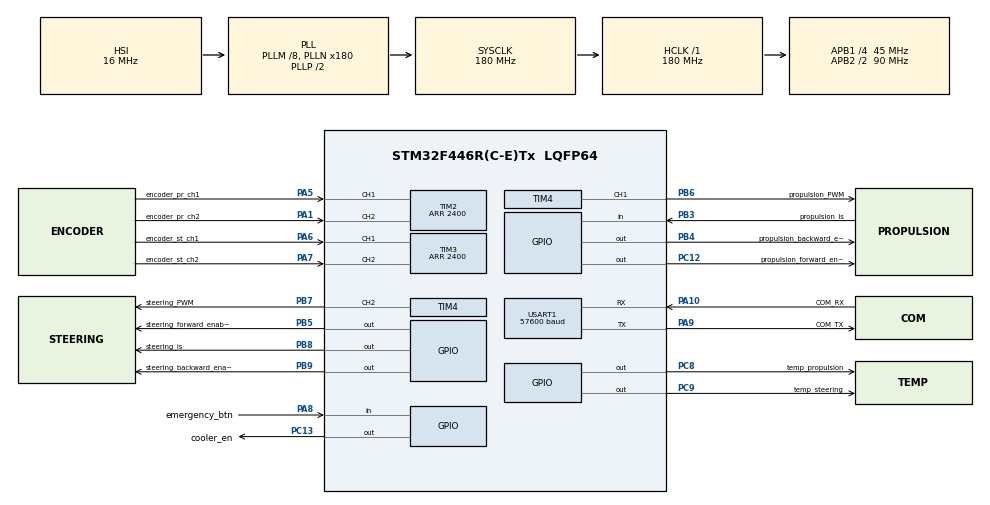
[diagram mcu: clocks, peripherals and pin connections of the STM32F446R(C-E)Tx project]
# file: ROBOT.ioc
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Dma.Request0=USART1_RX
Dma.Request1=USART1_TX
Dma.USART1_RX.0.Direction=DMA_PERIPH_TO_MEMORY
Dma.USART1_RX.0.FIFOMode=DMA_FIFOMODE_DISABLE
Dma.USART1_RX.0.Instance=DMA2_Stream2
Dma.USART1_RX.0.MemDataAlignment=DMA_MDATAALIGN_BYTE
Dma.USART1_RX.0.MemInc=DMA_MINC_ENABLE
Dma.USART1_RX.0.Mode=DMA_NORMAL
Dma.USART1_RX.0.PeriphDataAlignment=DMA_PDATAALIGN_BYTE
Dma.USART1_RX.0.PeriphInc=DMA_PINC_DISABLE
Dma.USART1_RX.0.Priority=DMA_PRIORITY_VERY_HIGH
Dma.USART1_TX.1.Direction=DMA_MEMORY_TO_PERIPH
Dma.USART1_TX.1.FIFOMode=DMA_FIFOMODE_DISABLE
Dma.USART1_TX.1.Instance=DMA2_Stream7
Dma.USART1_TX.1.MemDataAlignment=DMA_MDATAALIGN_BYTE
Dma.USART1_TX.1.MemInc=DMA_MINC_ENABLE
Dma.USART1_TX.1.Mode=DMA_NORMAL
Dma.USART1_TX.1.PeriphDataAlignment=DMA_PDATAALIGN_BYTE
Dma.USART1_TX.1.PeriphInc=DMA_PINC_DISABLE
Dma.USART1_TX.1.Priority=DMA_PRIORITY_VERY_HIGH
Mcu.Family=STM32F4
Mcu.Name=STM32F446R(C-E)Tx
Mcu.Package=LQFP64
NVIC.DMA2_Stream2_IRQn=true\:0\:0\:false\:false\:true\:false\:true
NVIC.DMA2_Stream7_IRQn=true\:0\:0\:false\:false\:true\:false\:true
NVIC.PriorityGroup=NVIC_PRIORITYGROUP_4
NVIC.TIM1_UP_TIM10_IRQn=true\:0\:0\:false\:false\:true\:false\:true
NVIC.TimeBase=TIM1_UP_TIM10_IRQn
NVIC.TimeBaseIP=TIM1
NVIC.USART1_IRQn=true\:0\:0\:false\:false\:true\:true\:true
PA1.GPIO_Label=encoder_pr_ch2
PA1.GPIO_PuPd=GPIO_PULLUP
PA1.Signal=S_TIM2_CH2
PA10.GPIO_Label=COM_RX
PA10.Mode=Asynchronous
PA10.Signal=USART1_RX
PA13.Mode=Serial_Wire
PA13.Signal=SYS_JTMS-SWDIO
PA14.Mode=Serial_Wire
PA14.Signal=SYS_JTCK-SWCLK
PA5.GPIO_Label=encoder_pr_ch1
PA5.GPIO_PuPd=GPIO_PULLUP
PA5.Signal=S_TIM2_CH1_ETR
PA6.GPIO_Label=encoder_st_ch1
PA6.GPIO_PuPd=GPIO_PULLUP
PA6.Signal=S_TIM3_CH1
PA7.GPIO_Label=encoder_st_ch2
PA7.GPIO_PuPd=GPIO_PULLUP
PA7.Signal=S_TIM3_CH2
PA8.GPIO_Label=emergency_btn
PA8.GPIO_PuPd=GPIO_PULLUP
PA8.Signal=GPIO_Input
PA9.GPIO_Label=COM_TX
PA9.Mode=Asynchronous
PA9.Signal=USART1_TX
PB3.GPIO_Label=propulsion_is
PB3.Signal=GPIO_Input
PB4.GPIO_Label=propulsion_backward_enable
PB4.GPIO_Speed=GPIO_SPEED_FREQ_VERY_HIGH
PB4.PinState=GPIO_PIN_RESET
PB4.Signal=GPIO_Output
PB5.GPIO_Label=steering_forward_enable
PB5.GPIO_Speed=GPIO_SPEED_FREQ_VERY_HIGH
PB5.PinState=GPIO_PIN_RESET
PB5.Signal=GPIO_Output
PB6.GPIO_Label=propulsion_PWM
PB6.GPIO_Speed=GPIO_SPEED_FREQ_VERY_HIGH
PB6.Signal=S_TIM4_CH1
PB7.GPIO_Label=steering_PWM
PB7.GPIO_Speed=GPIO_SPEED_FREQ_VERY_HIGH
PB7.Signal=S_TIM4_CH2
PB8.GPIO_Label=steering_is
PB8.Signal=GPIO_Output
PB9.GPIO_Label=steering_backward_enable
PB9.GPIO_Speed=GPIO_SPEED_FREQ_VERY_HIGH
PB9.PinState=GPIO_PIN_RESET
PB9.Signal=GPIO_Output
PC12.GPIO_Label=propulsion_forward_enable
PC12.GPIO_Speed=GPIO_SPEED_FREQ_VERY_HIGH
PC12.PinState=GPIO_PIN_RESET
PC12.Signal=GPIO_Output
PC13.GPIO_Label=cooler_en
PC13.Signal=GPIO_Output
PC8.GPIO_Label=temp_propulsion
PC8.GPIO_ModeDefaultOutputPP=GPIO_MODE_OUTPUT_OD
PC8.GPIO_PuPd=GPIO_PULLUP
PC8.GPIO_Speed=GPIO_SPEED_FREQ_VERY_HIGH
PC8.Signal=GPIO_Output
PC9.GPIO_Label=temp_steering
PC9.GPIO_ModeDefaultOutputPP=GPIO_MODE_OUTPUT_OD
PC9.GPIO_PuPd=GPIO_PULLUP
PC9.GPIO_Speed=GPIO_SPEED_FREQ_VERY_HIGH
PC9.Signal=GPIO_Output
ProjectManager.HeapSize=0x1800
ProjectManager.StackSize=0x1800
ProjectManager.TargetToolchain=STM32CubeIDE
RCC.AHBFreq_Value=180000000
RCC.APB1CLKDivider=RCC_HCLK_DIV4
RCC.APB1Freq_Value=45000000
RCC.APB1TimFreq_Value=90000000
RCC.APB2CLKDivider=RCC_HCLK_DIV2
RCC.APB2Freq_Value=90000000
RCC.APB2TimFreq_Value=180000000
RCC.CortexFreq_Value=180000000
RCC.HCLKFreq_Value=180000000
RCC.PLLM=8
RCC.PLLN=180
RCC.SYSCLKFreq_VALUE=180000000
RCC.SYSCLKSource=RCC_SYSCLKSOURCE_PLLCLK
RCC.USBFreq_Value=180000000
RCC.VCOOutputFreq_Value=360000000
SH.S_TIM2_CH1_ETR.0=TIM2_CH1,Encoder_Interface
SH.S_TIM2_CH2.0=TIM2_CH2,Encoder_Interface
SH.S_TIM3_CH1.0=TIM3_CH1,Encoder_Interface
SH.S_TIM3_CH2.0=TIM3_CH2,Encoder_Interface
SH.S_TIM4_CH1.0=TIM4_CH1,PWM Generation1 CH1
SH.S_TIM4_CH2.0=TIM4_CH2,PWM Generation2 CH2
TIM2.EncoderMode=TIM_ENCODERMODE_TI12
TIM2.IC1Filter=10
TIM2.IC2Filter=10
TIM2.Period=2400
TIM3.EncoderMode=TIM_ENCODERMODE_TI12
TIM3.IC1Filter=10
TIM3.IC2Filter=10
TIM3.Period=2400
TIM4.Channel-PWM\ Generation1\ CH1=TIM_CHANNEL_1
TIM4.Channel-PWM\ Generation2\ CH2=TIM_CHANNEL_2
TIM4.OCFastMode_PWM-PWM\ Generation1\ CH1=TIM_OCFAST_ENABLE
TIM4.OCFastMode_PWM-PWM\ Generation2\ CH2=TIM_OCFAST_ENABLE
TIM4.OCPolarity_1=TIM_OCPOLARITY_HIGH
TIM4.OCPolarity_2=TIM_OCPOLARITY_HIGH
TIM4.Period=300
TIM4.Prescaler=1199
TIM5.CounterMode=TIM_COUNTERMODE_DOWN
TIM5.Period=0
TIM5.Prescaler=(SystemCoreClock/1e6)/4 -1
USART1.BaudRate=57600
USART1.VirtualMode=VM_ASYNC
VP_IWDG_VS_IWDG.Mode=IWDG_Activate
VP_SYS_VS_tim1.Mode=TIM1
VP_TIM5_VS_ClockSourceINT.Mode=Internal
board=custom

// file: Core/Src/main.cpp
/* USER CODE BEGIN Header */
/**
  ******************************************************************************
  * @file           : main.c
  * @brief          : Main program body
  ******************************************************************************
  * @attention
  *
  * <h2><center>&copy; Copyright (c) 2020 STMicroelectronics.
  * All rights reserved.</center></h2>
  *
  * This software component is licensed by ST under BSD 3-Clause license,
  * the "License"; You may not use this file except in compliance with the
  * License. You may obtain a copy of the License at:
  *                        opensource.org/licenses/BSD-3-Clause
  *
  ******************************************************************************
  */
/* USER CODE END Header */
#include "main.h"
#include "dma.h"
#include "tim.h"
#include "usart.h"
#include "gpio.h"
#include "iwdg.h"

/* USER CODE BEGIN Includes */
#include <string.h>
#include <stdio.h>
#include <mainpp.hpp>
#include <../Objects/temperature_class/Temperature_DS18B20.h>

/* USER CODE END Includes */

void SystemClock_Config(void);

int main(void)
{

  /* MCU Configuration--------------------------------------------------------*/

  /* Reset of all peripherals, Initializes the Flash interface and the Systick. */
  HAL_Init();

  /* Configure the system clock */
  SystemClock_Config();

  /* Initialize all configured peripherals */
  MX_GPIO_Init();
  MX_DMA_Init();
  MX_TIM4_Init();
  MX_USART1_UART_Init();
  MX_TIM2_Init();
  MX_TIM3_Init();
  MX_TIM5_Init();
  MX_IWDG_Init();
  /* USER CODE BEGIN 2 */
  setup();
  /* USER CODE END 2 */

  /* Infinite loop */
  /* USER CODE BEGIN WHILE */

  while (1)
  {
	  HAL_IWDG_Refresh(&hiwdg);
	  loop();
    /* USER CODE END WHILE */

  }
}

void SystemClock_Config(void)
{
  RCC_OscInitTypeDef RCC_OscInitStruct = {0};
  RCC_ClkInitTypeDef RCC_ClkInitStruct = {0};

  /** Configure the main internal regulator output voltage
  */
  __HAL_RCC_PWR_CLK_ENABLE();
  __HAL_PWR_VOLTAGESCALING_CONFIG(PWR_REGULATOR_VOLTAGE_SCALE1);
  /** Initializes the RCC Oscillators according to the specified parameters
  * in the RCC_OscInitTypeDef structure.
  */
  RCC_OscInitStruct.OscillatorType = RCC_OSCILLATORTYPE_HSI;
  RCC_OscInitStruct.HSIState = RCC_HSI_ON;
  RCC_OscInitStruct.HSICalibrationValue = RCC_HSICALIBRATION_DEFAULT;
  RCC_OscInitStruct.PLL.PLLState = RCC_PLL_ON;
  RCC_OscInitStruct.PLL.PLLSource = RCC_PLLSOURCE_HSI;
  RCC_OscInitStruct.PLL.PLLM = 8;
  RCC_OscInitStruct.PLL.PLLN = 180;
  RCC_OscInitStruct.PLL.PLLP = RCC_PLLP_DIV2;
  RCC_OscInitStruct.PLL.PLLQ = 2;
  RCC_OscInitStruct.PLL.PLLR = 2;
  if (HAL_RCC_OscConfig(&RCC_OscInitStruct) != HAL_OK)
  {
    Error_Handler();
  }
  /** Activate the Over-Drive mode
  */
  if (HAL_PWREx_EnableOverDrive() != HAL_OK)
  {
    Error_Handler();
  }
  /** Initializes the CPU, AHB and APB buses clocks
  */
  RCC_ClkInitStruct.ClockType = RCC_CLOCKTYPE_HCLK|RCC_CLOCKTYPE_SYSCLK
                              |RCC_CLOCKTYPE_PCLK1|RCC_CLOCKTYPE_PCLK2;
  RCC_ClkInitStruct.SYSCLKSource = RCC_SYSCLKSOURCE_PLLCLK;
  RCC_ClkInitStruct.AHBCLKDivider = RCC_SYSCLK_DIV1;
  RCC_ClkInitStruct.APB1CLKDivider = RCC_HCLK_DIV4;
  RCC_ClkInitStruct.APB2CLKDivider = RCC_HCLK_DIV2;

  if (HAL_RCC_ClockConfig(&RCC_ClkInitStruct, FLASH_LATENCY_5) != HAL_OK)
  {
    Error_Handler();
  }
}

 /**
  * @brief  Period elapsed callback in non blocking mode
  * @note   This function is called  when TIM1 interrupt took place, inside
  * HAL_TIM_IRQHandler(). It makes a direct call to HAL_IncTick() to increment
  * a global variable "uwTick" used as application time base.
  * @param  htim : TIM handle
  * @retval None
  */
void HAL_TIM_PeriodElapsedCallback(TIM_HandleTypeDef *htim)
{
  if (htim->Instance == TIM1) {
    HAL_IncTick();
  }
}

void Error_Handler(void)
{
  __disable_irq();
  while (1)
  {
  }
}

/************************ (C) COPYRIGHT STMicroelectronics *****END OF FILE****/
